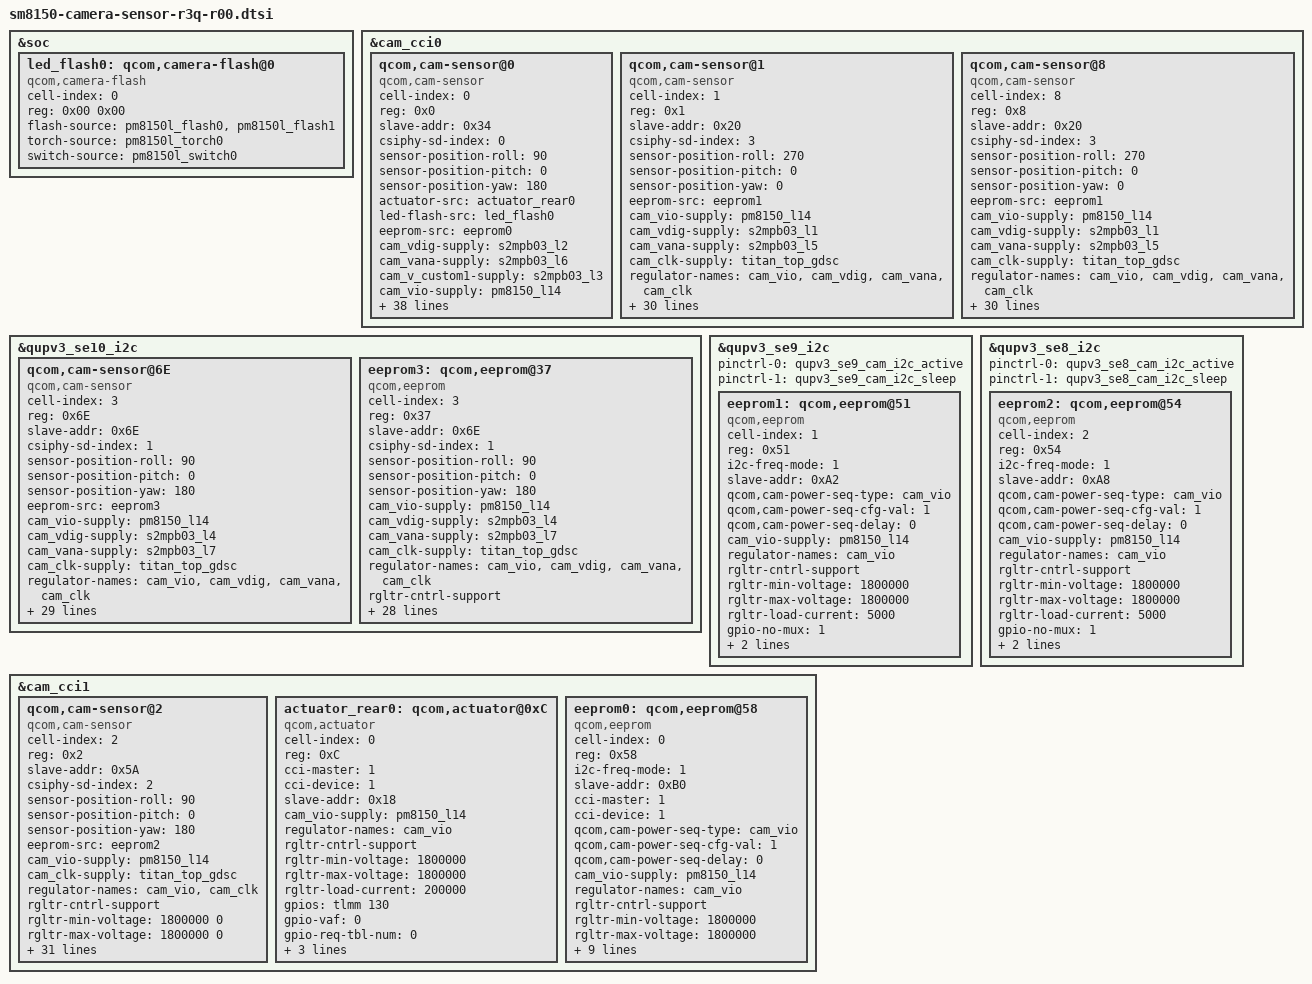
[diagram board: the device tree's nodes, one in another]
&soc {
        led_flash0: qcom,camera-flash@0 {
              cell-index = <0>;
              reg = <0x00 0x00>;
              compatible = "qcom,camera-flash";
              flash-source = <&pm8150l_flash0 &pm8150l_flash1>;
              torch-source = <&pm8150l_torch0>;
              switch-source = <&pm8150l_switch0>;        
              status = "ok";
        };
};

&cam_cci0 {

	qcom,cam-sensor@0 {
		cell-index = <0>;
		compatible = "qcom,cam-sensor";
		reg = <0x0>;
		slave-addr = <0x34>;
		csiphy-sd-index = <0>;
		sensor-position-roll = <90>;
		sensor-position-pitch = <0>;
		sensor-position-yaw = <180>;
		actuator-src = <&actuator_rear0>;
		led-flash-src = <&led_flash0>;
		eeprom-src = <&eeprom0>; 

		// Regulators
		cam_vdig-supply = <&s2mpb03_l2>;  // digital 1.1
		cam_vana-supply = <&s2mpb03_l6>; // analog 2.9 
		cam_v_custom1-supply = <&s2mpb03_l3>;	// analog2 1.8
		cam_vio-supply = <&pm8150_l14>; // vio
		cam_clk-supply = <&titan_top_gdsc>;
		
		regulator-names = "cam_vdig", "cam_vana", "cam_v_custom1", "cam_vio","cam_clk";
		rgltr-cntrl-support;
		rgltr-min-voltage = <1100000 2900000 1800000 1800000 0>;
		rgltr-max-voltage = <1100000 2900000 1800000 1800000 0>;
		rgltr-load-current = <200000 200000 200000 200000 0>;

		// GPIO
		gpio-no-mux = <0>;
		pinctrl-names = "cam_default", "cam_suspend";
		pinctrl-0 = <&cam_sensor_mclk0_active &cam_sensor_rear1_active>;
		pinctrl-1 = <&cam_sensor_mclk0_suspend &cam_sensor_rear1_suspend>;
		gpios = <&tlmm 13 0>,
			<&tlmm 92 0>,
			<&tlmm 130 0>;
		gpio-reset = <1>;
		gpio-vaf = <2>;
		gpio-req-tbl-num = <0 1 2>;
		gpio-req-tbl-flags = <1 0 0>;
		gpio-req-tbl-label = "CAMIF_MCLK0","CAM_RESET0", "CAM_VAF";

		sensor-mode = <0>;
		cci-master = <0>;
		status = "ok";
		clocks = <&clock_camcc CAM_CC_MCLK0_CLK>;
		clock-names = "cam_clk";
		clock-cntl-level = "turbo";
		clock-rates = <24000000>;
		cam,isp = <0>;                  // 0 : INT , 1 : EXT , 2 : SOC
		cam,cal_memory = <2>;           // 0 : N , 1 : FROM , 2 : EEPROM , 3 : OTP
		cam,read_version = <0>;         // 0 : SYSFS , 1 : CAMON
		cam,core_voltage = <0>;         // 0 : N , 1 : Y
		cam,upgrade = <0>;              // 0 : N , 1 : SYSFS , 2 : CAMON
		cam,fw_write = <0>;             // 0 : N , 1 : OS , 2 : SD , 3 : ALL
		cam,fw_dump = <0>;              // 0 : N , 1 : Y
		cam,companion_chip = <0>;       // 0 : N , 1 : Y
		cam,ois = <0>;                  // 0 : N , 1 : Y
		cam,dual_open = <0>;            // 0 : N , 1 : Y
		cam,valid = <1>;                // 0 : N , 1 : Y
	};
	
        qcom,cam-sensor@1 {
		cell-index = <1>;
		compatible = "qcom,cam-sensor";
		reg = <0x1>;
		slave-addr = <0x20>;
		csiphy-sd-index = <3>;
		sensor-position-roll = <270>;
		sensor-position-pitch = <0>;
		sensor-position-yaw = <0>;
		eeprom-src = <&eeprom1>;
		cam_vio-supply = <&pm8150_l14>;
		cam_vdig-supply = <&s2mpb03_l1>;
		cam_vana-supply = <&s2mpb03_l5>;
		cam_clk-supply = <&titan_top_gdsc>;
		regulator-names = "cam_vio", "cam_vdig", "cam_vana", "cam_clk";
		rgltr-cntrl-support;
		rgltr-min-voltage = <1800000 1050000 2800000 0>;
		rgltr-max-voltage = <1800000 1050000 2800000 0>;
		rgltr-load-current = <200000 200000 200000 0>;
		gpio-no-mux = <0>;
		pinctrl-names = "cam_default", "cam_suspend";
		pinctrl-0 = <&cam_sensor_mclk2_active &cam_sensor_active_front>;
		pinctrl-1 = <&cam_sensor_mclk2_suspend &cam_sensor_suspend_front>;
		gpios = <&tlmm 15 0>, /*VTCAM_MCLK*/
			<&tlmm 82 0>; /*VTCAM_RST*/
		gpio-reset = <1>;
		gpio-req-tbl-num = <0 1>;
		gpio-req-tbl-flags = <1 0>;
		gpio-req-tbl-label = "CAMIF_MCLK2", "CAM_RESET2";

		sensor-mode = <0>;
		cci-master = <1>;
		status = "ok";
		clocks = <&clock_camcc CAM_CC_MCLK2_CLK>;
		clock-names = "cam_clk";
		clock-cntl-level = "turbo";
		clock-rates = <24000000>;

		cam,isp = <0>;                  // 0 : INT , 1 : EXT , 2 : SOC
		cam,cal_memory = <2>;           // 0 : N , 1 : FROM , 2 : EEPROM , 3 : OTP
		cam,read_version = <0>;         // 0 : SYSFS , 1 : CAMON
		cam,core_voltage = <0>;         // 0 : N , 1 : Y
		cam,upgrade = <0>;              // 0 : N , 1 : SYSFS , 2 : CAMON
		cam,fw_write = <0>;             // 0 : N , 1 : OS , 2 : SD , 3 : ALL
		cam,fw_dump = <0>;              // 0 : N , 1 : Y
		cam,companion_chip = <0>;       // 0 : N , 1 : Y
		cam,ois = <0>;                  // 0 : N , 1 : Y
		cam,dual_open = <0>;            // 0 : N , 1 : Y
		cam,valid = <1>;                // 0 : N , 1 : Y
	};

        qcom,cam-sensor@8 {
		cell-index = <8>;
		compatible = "qcom,cam-sensor";
		reg = <0x8>;
		slave-addr = <0x20>;
		csiphy-sd-index = <3>;
		sensor-position-roll = <270>;
		sensor-position-pitch = <0>;
		sensor-position-yaw = <0>;
		eeprom-src = <&eeprom1>;
		cam_vio-supply = <&pm8150_l14>;
		cam_vdig-supply = <&s2mpb03_l1>;
		cam_vana-supply = <&s2mpb03_l5>;
		cam_clk-supply = <&titan_top_gdsc>;
		regulator-names = "cam_vio", "cam_vdig", "cam_vana", "cam_clk";
		rgltr-cntrl-support;
		rgltr-min-voltage = <1800000 1050000 2800000 0>;
		rgltr-max-voltage = <1800000 1050000 2800000 0>;
		rgltr-load-current = <200000 200000 200000 0>;
		gpio-no-mux = <0>;
		pinctrl-names = "cam_default", "cam_suspend";
		pinctrl-0 = <&cam_sensor_mclk2_active &cam_sensor_active_front>;
		pinctrl-1 = <&cam_sensor_mclk2_suspend &cam_sensor_suspend_front>;
		gpios = <&tlmm 15 0>, /*VTCAM_MCLK*/
			<&tlmm 82 0>; /*VTCAM_RST*/
		gpio-reset = <1>;
		gpio-req-tbl-num = <0 1>;
		gpio-req-tbl-flags = <1 0>;
		gpio-req-tbl-label = "CAMIF_MCLK2", "CAM_RESET2";

		sensor-mode = <0>;
		cci-master = <1>;
		status = "ok";
		clocks = <&clock_camcc CAM_CC_MCLK2_CLK>;
		clock-names = "cam_clk";
		clock-cntl-level = "turbo";
		clock-rates = <24000000>;

		cam,isp = <0>;                  // 0 : INT , 1 : EXT , 2 : SOC
		cam,cal_memory = <2>;           // 0 : N , 1 : FROM , 2 : EEPROM , 3 : OTP
		cam,read_version = <0>;         // 0 : SYSFS , 1 : CAMON
		cam,core_voltage = <0>;         // 0 : N , 1 : Y
		cam,upgrade = <0>;              // 0 : N , 1 : SYSFS , 2 : CAMON
		cam,fw_write = <0>;             // 0 : N , 1 : OS , 2 : SD , 3 : ALL
		cam,fw_dump = <0>;              // 0 : N , 1 : Y
		cam,companion_chip = <0>;       // 0 : N , 1 : Y
		cam,ois = <0>;                  // 0 : N , 1 : Y
		cam,dual_open = <0>;            // 0 : N , 1 : Y
		cam,valid = <1>;                // 0 : N , 1 : Y
	};
	
};

&qupv3_se10_i2c {
	status = "ok";
	
		qcom,cam-sensor@6E {
			cell-index = <3>;
			compatible = "qcom,cam-sensor";
			reg = <0x6E>;
			slave-addr = <0x6E>;
			csiphy-sd-index = <1>;
			sensor-position-roll = <90>;
			sensor-position-pitch = <0>;
			sensor-position-yaw = <180>;
			eeprom-src = <&eeprom3>;			
			cam_vio-supply = <&pm8150_l14>;
			cam_vdig-supply = <&s2mpb03_l4>;
			cam_vana-supply = <&s2mpb03_l7>;
			cam_clk-supply = <&titan_top_gdsc>; 
			regulator-names = "cam_vio", "cam_vdig", "cam_vana", "cam_clk";
			rgltr-cntrl-support;
			rgltr-min-voltage = <1800000 1200000 2800000 0>;
			rgltr-max-voltage = <1800000 1200000 2800000 0>;
			rgltr-load-current = <200000 200000 200000 0>;
			gpio-no-mux = <0>;
			pinctrl-names = "cam_default", "cam_suspend";
			pinctrl-0 = <&cam_sensor_mclk3_active &cam_sensor_rear2_active>;
			pinctrl-1 = <&cam_sensor_mclk3_suspend &cam_sensor_rear2_suspend>;
			gpios = <&tlmm 16 0>,
			        <&tlmm 21 0>;
			gpio-reset = <1>;
			gpio-req-tbl-num = <0 1>;
			gpio-req-tbl-flags = <1 0>;
			gpio-req-tbl-label = "CAMIF_MCLK3", "CAM_RESET3";

			sensor-mode = <0>;
			status = "ok";
			clocks = <&clock_camcc CAM_CC_MCLK3_CLK>;
			clock-names = "cam_clk";
			clock-cntl-level = "turbo";
			clock-rates = <24000000>;

			cam,isp = <0>;                  // 0 : INT , 1 : EXT , 2 : SOC
			cam,cal_memory = <2>;           // 0 : N , 1 : FROM , 2 : EEPROM , 3 : OTP
			cam,read_version = <0>;         // 0 : SYSFS , 1 : CAMON
			cam,core_voltage = <0>;         // 0 : N , 1 : Y
			cam,upgrade = <0>;              // 0 : N , 1 : SYSFS , 2 : CAMON
			cam,fw_write = <0>;             // 0 : N , 1 : OS , 2 : SD , 3 : ALL
			cam,fw_dump = <0>;              // 0 : N , 1 : Y
			cam,companion_chip = <0>;       // 0 : N , 1 : Y
			cam,ois = <0>;                  // 0 : N , 1 : Y
			cam,dual_open = <0>;            // 0 : N , 1 : Y
			cam,valid = <1>;                // 0 : N , 1 : Y
		};	
		
		eeprom3: qcom,eeprom@37 {
			cell-index = <3>;
			compatible = "qcom,eeprom";
			reg = <0x37>;
			slave-addr = <0x6E>;
			csiphy-sd-index = <1>;
			sensor-position-roll = <90>;
			sensor-position-pitch = <0>;
			sensor-position-yaw = <180>;		
			cam_vio-supply = <&pm8150_l14>;
			cam_vdig-supply = <&s2mpb03_l4>;
			cam_vana-supply = <&s2mpb03_l7>;
			cam_clk-supply = <&titan_top_gdsc>; 
			regulator-names = "cam_vio", "cam_vdig", "cam_vana", "cam_clk";
			rgltr-cntrl-support;
			rgltr-min-voltage = <1800000 1200000 2800000 0>;
			rgltr-max-voltage = <1800000 1200000 2800000 0>;
			rgltr-load-current = <200000 200000 200000 0>;
			gpio-no-mux = <0>;
			pinctrl-names = "cam_default", "cam_suspend";
			pinctrl-0 = <&cam_sensor_mclk3_active &cam_sensor_rear2_active>;
			pinctrl-1 = <&cam_sensor_mclk3_suspend &cam_sensor_rear2_suspend>;
			gpios = <&tlmm 16 0>,
			        <&tlmm 21 0>;
			gpio-reset = <1>;
			gpio-req-tbl-num = <0 1>;
			gpio-req-tbl-flags = <1 0>;
			gpio-req-tbl-label = "CAMIF_MCLK3", "CAM_RESET3";

			sensor-mode = <0>;
			status = "ok";
			clocks = <&clock_camcc CAM_CC_MCLK3_CLK>;
			clock-names = "cam_clk";
			clock-cntl-level = "turbo";
			clock-rates = <24000000>;

			cam,isp = <0>;                  // 0 : INT , 1 : EXT , 2 : SOC
			cam,cal_memory = <2>;           // 0 : N , 1 : FROM , 2 : EEPROM , 3 : OTP
			cam,read_version = <0>;         // 0 : SYSFS , 1 : CAMON
			cam,core_voltage = <0>;         // 0 : N , 1 : Y
			cam,upgrade = <0>;              // 0 : N , 1 : SYSFS , 2 : CAMON
			cam,fw_write = <0>;             // 0 : N , 1 : OS , 2 : SD , 3 : ALL
			cam,fw_dump = <0>;              // 0 : N , 1 : Y
			cam,companion_chip = <0>;       // 0 : N , 1 : Y
			cam,ois = <0>;                  // 0 : N , 1 : Y
			cam,dual_open = <0>;            // 0 : N , 1 : Y
			cam,valid = <1>;                // 0 : N , 1 : Y
		};	
};

&qupv3_se9_i2c {
        pinctrl-0 = <&qupv3_se9_cam_i2c_active>;
        pinctrl-1 = <&qupv3_se9_cam_i2c_sleep>;
        status = "ok";
        eeprom1: qcom,eeprom@51 {
                cell-index = <1>;
                reg = <0x51>;
                compatible = "qcom,eeprom";
                i2c-freq-mode = <1>;
                slave-addr = <0xA2>;

                //cci-master = <1>;
                //cci-device = <1>;
                qcom,cam-power-seq-type = "cam_vio";
                qcom,cam-power-seq-cfg-val = <1>;
                qcom,cam-power-seq-delay = <0>;
                cam_vio-supply = <&pm8150_l14>; /* VDD_MAINCAM_IO_1P8 */
                regulator-names = "cam_vio";
                rgltr-cntrl-support;
                rgltr-min-voltage = <1800000>;
                rgltr-max-voltage = <1800000>;
                rgltr-load-current = <5000>;
		
                gpio-no-mux = <1>;
                sensor-position = <0>;
                sensor-mode = <0>;
                status = "ok";
        };
};

&qupv3_se8_i2c {
        pinctrl-0 = <&qupv3_se8_cam_i2c_active>;
        pinctrl-1 = <&qupv3_se8_cam_i2c_sleep>;
        status = "ok";
        eeprom2: qcom,eeprom@54 {
                cell-index = <2>;
                reg = <0x54>;
                compatible = "qcom,eeprom";
                i2c-freq-mode = <1>;
                slave-addr = <0xA8>;

                //cci-master = <0>;
                //cci-device = <1>;
                qcom,cam-power-seq-type = "cam_vio";
                qcom,cam-power-seq-cfg-val = <1>;
                qcom,cam-power-seq-delay = <0>;
                cam_vio-supply = <&pm8150_l14>; /* VDD_MAINCAM_IO_1P8 */
                regulator-names = "cam_vio";
                rgltr-cntrl-support;
                rgltr-min-voltage = <1800000>;
                rgltr-max-voltage = <1800000>;
                rgltr-load-current = <5000>;
		
                gpio-no-mux = <1>;
                sensor-position = <0>;
                sensor-mode = <0>;
                status = "ok";
        };    
};

&cam_cci1 {

	qcom,cam-sensor@2 {
		cell-index = <2>; /*REAR UW 8M*/
		compatible = "qcom,cam-sensor";
		reg = <0x2>;
		slave-addr = <0x5A>;
		csiphy-sd-index = <2>;
		sensor-position-roll = <90>;
		sensor-position-pitch = <0>;
		sensor-position-yaw = <180>;
		/*actuator-src = <&actuator1>;*/
		eeprom-src = <&eeprom2>;

		// LDO
		cam_vio-supply = <&pm8150_l14>;
		cam_clk-supply = <&titan_top_gdsc>; 
		regulator-names = "cam_vio", "cam_clk";
		rgltr-cntrl-support;
		rgltr-min-voltage = <1800000 0>;
		rgltr-max-voltage = <1800000 0>;
		rgltr-load-current = <200000 0>;

		// GPIO
		gpio-no-mux = <0>;
		pinctrl-names = "cam_default", "cam_suspend";
		pinctrl-0 = <&cam_sensor_mclk1_active &cam_sensor_uw1_active>;
		pinctrl-1 = <&cam_sensor_mclk1_suspend &cam_sensor_uw1_suspend>;
		gpios = <&tlmm 14 0>, /*UWCAM_MCLK*/
			<&tlmm 22 0>, /*UWCAM_RST_N*/
			<&tlmm 129 0>, /*UWCAM_AVDD_2P8*/
			<&tlmm 131 0>; /* UWCAM_DVDD_1P2*/
		gpio-reset = <1>;
		gpio-vana = <2>;
		gpio-vdig = <3>;
		gpio-req-tbl-num = <0 1 2 3>;
		gpio-req-tbl-flags = <1 0 0 0>;
		gpio-req-tbl-label = "CAMIF_MCLK1",
				     "CAM_RESET1",
				     "CAM_VANA1",
				     "CAM_VDIG1";
		sensor-mode = <0>;
		cci-master = <0>;
		cci-device = <1>;
		status = "ok";
		clocks = <&clock_camcc CAM_CC_MCLK1_CLK>;
		clock-names = "cam_clk";
		clock-cntl-level = "turbo";
		clock-rates = <24000000>;

		cam,isp = <0>;                  // 0 : INT , 1 : EXT , 2 : SOC
		cam,cal_memory = <2>;           // 0 : N , 1 : FROM , 2 : EEPROM , 3 : OTP
		cam,read_version = <0>;         // 0 : SYSFS , 1 : CAMON
		cam,core_voltage = <0>;         // 0 : N , 1 : Y
		cam,upgrade = <0>;              // 0 : N , 1 : SYSFS , 2 : CAMON
		cam,fw_write = <0>;             // 0 : N , 1 : OS , 2 : SD , 3 : ALL
		cam,fw_dump = <0>;              // 0 : N , 1 : Y
		cam,companion_chip = <0>;       // 0 : N , 1 : Y
		cam,ois = <0>;                  // 0 : N , 1 : Y
		cam,dual_open = <0>;            // 0 : N , 1 : Y
		cam,valid = <1>;                // 0 : N , 1 : Y
	};
	
	actuator_rear0: qcom,actuator@0xC {
		cell-index = <0>;
		reg = <0xC>;
		cci-master = <1>;
		cci-device = <1>;
		slave-addr = <0x18>;
		compatible = "qcom,actuator";
		cam_vio-supply = <&pm8150_l14>;
		regulator-names = "cam_vio";
		rgltr-cntrl-support;
		rgltr-min-voltage = <1800000>;
		rgltr-max-voltage = <1800000>;
		rgltr-load-current = <200000>;
		
		gpios = <&tlmm 130 0> ; /* VAF configure GPIO pin */
		gpio-vaf = <0>;
		gpio-req-tbl-num = <0>;
		gpio-req-tbl-flags = <0>;
		gpio-req-tbl-label = "CAM_VAF";
		sensor-mode = <0>;
	};	
	
	eeprom0: qcom,eeprom@58 {
		cell-index = <0>;
		reg = <0x58>;
		compatible = "qcom,eeprom";
		i2c-freq-mode = <1>;
		slave-addr =<0xB0>; // I2C = B0
		cci-master = <1>;
		cci-device = <1>;
		qcom,cam-power-seq-type = "cam_vio";
		qcom,cam-power-seq-cfg-val = <1>;
		qcom,cam-power-seq-delay = <0>;
		cam_vio-supply = <&pm8150_l14>; /* VDD_MAINCAM_IO_1P8 */
		regulator-names = "cam_vio";
		rgltr-cntrl-support;
		rgltr-min-voltage = <1800000>;
		rgltr-max-voltage = <1800000>;
		rgltr-load-current = <5000>;
		gpios = <&tlmm 130 0> ; /* VAF configure GPIO pin */
		gpio-vaf = <0>;
		gpio-req-tbl-num = <0>;
		gpio-req-tbl-flags = <0>;
		gpio-req-tbl-label = "CAM_VAF";
		
		gpio-no-mux = <1>;
		sensor-position = <0>;
		sensor-mode = <0>;
		status = "ok";
	};	
};
